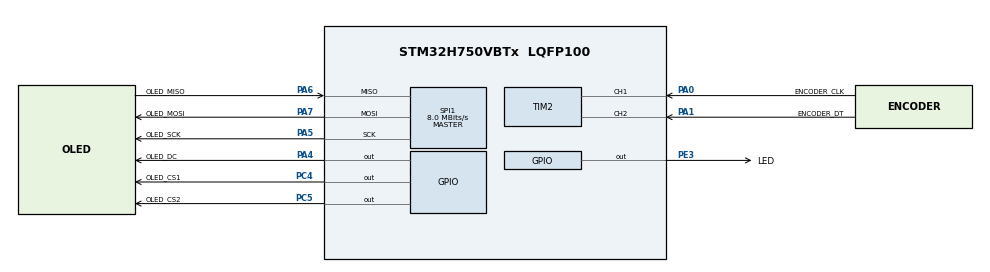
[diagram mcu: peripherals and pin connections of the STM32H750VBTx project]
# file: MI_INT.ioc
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CORTEX_M7.CPU_DCache=Enabled
CORTEX_M7.CPU_ICache=Enabled
CORTEX_M7.default_mode_Activation=1
Mcu.Family=STM32H7
Mcu.Name=STM32H750VBTx
Mcu.Package=LQFP100
NVIC.PriorityGroup=NVIC_PRIORITYGROUP_4
PA0.GPIO_Label=ENCODER_CLK
PA0.Signal=S_TIM2_CH1_ETR
PA1.GPIO_Label=ENCODER_DT
PA1.Signal=S_TIM2_CH2
PA13\ (JTMS/SWDIO).Mode=Serial_Wire
PA13\ (JTMS/SWDIO).Signal=DEBUG_JTMS-SWDIO
PA14\ (JTCK/SWCLK).Mode=Serial_Wire
PA14\ (JTCK/SWCLK).Signal=DEBUG_JTCK-SWCLK
PA4.GPIO_Label=OLED_DC
PA4.Signal=GPIO_Output
PA5.GPIO_Label=OLED_SCK
PA5.Mode=Full_Duplex_Master
PA5.Signal=SPI1_SCK
PA6.GPIO_Label=OLED_MISO
PA6.Mode=Full_Duplex_Master
PA6.Signal=SPI1_MISO
PA7.GPIO_Label=OLED_MOSI
PA7.Mode=Full_Duplex_Master
PA7.Signal=SPI1_MOSI
PC14-OSC32_IN\ (OSC32_IN).Mode=LSE-External-Oscillator
PC14-OSC32_IN\ (OSC32_IN).Signal=RCC_OSC32_IN
PC15-OSC32_OUT\ (OSC32_OUT).Mode=LSE-External-Oscillator
PC15-OSC32_OUT\ (OSC32_OUT).Signal=RCC_OSC32_OUT
PC4.GPIO_Label=OLED_CS1
PC4.Signal=GPIO_Output
PC5.GPIO_Label=OLED_CS2
PC5.Signal=GPIO_Output
PE3.GPIO_Label=LED
PE3.Signal=GPIO_Output
PH0-OSC_IN\ (PH0).Mode=HSE-External-Oscillator
PH0-OSC_IN\ (PH0).Signal=RCC_OSC_IN
PH1-OSC_OUT\ (PH1).Mode=HSE-External-Oscillator
PH1-OSC_OUT\ (PH1).Signal=RCC_OSC_OUT
ProjectManager.HeapSize=0x200
ProjectManager.StackSize=0x800
ProjectManager.TargetToolchain=MDK-ARM V5.32
RCC.ADCFreq_Value=16000000
RCC.APB1Freq_Value=120000000
RCC.APB2Freq_Value=120000000
RCC.APB3Freq_Value=120000000
RCC.APB4Freq_Value=120000000
RCC.CortexFreq_Value=480000000
RCC.D1PPRE=RCC_APB3_DIV2
RCC.D2PPRE1=RCC_APB1_DIV2
RCC.D2PPRE2=RCC_APB2_DIV2
RCC.D3PPRE=RCC_APB4_DIV2
RCC.DIVM1=5
RCC.DIVM2=25
RCC.DIVN1=192
RCC.DIVN2=256
RCC.DIVP2=16
RCC.DIVQ1=5
RCC.HCLKFreq_Value=240000000
RCC.HPRE=RCC_HCLK_DIV2
RCC.PLLFRACN=0
RCC.PLLSourceVirtual=RCC_PLLSOURCE_HSE
RCC.SPI123CLockSelection=RCC_SPI123CLKSOURCE_PLL2
RCC.SYSCLKFreq_VALUE=480000000
RCC.SYSCLKSource=RCC_SYSCLKSOURCE_PLLCLK
RCC.USBFreq_Value=192000000
SH.S_TIM2_CH1_ETR.0=TIM2_CH1,Encoder_Interface
SH.S_TIM2_CH2.0=TIM2_CH2,Encoder_Interface
SPI1.BaudRatePrescaler=SPI_BAUDRATEPRESCALER_2
SPI1.CLKPhase=SPI_PHASE_2EDGE
SPI1.CLKPolarity=SPI_POLARITY_HIGH
SPI1.CalculateBaudRate=8.0 MBits/s
SPI1.DataSize=SPI_DATASIZE_8BIT
SPI1.Direction=SPI_DIRECTION_2LINES
SPI1.Mode=SPI_MODE_MASTER
SPI1.NSSPMode=SPI_NSS_PULSE_DISABLE
SPI1.VirtualType=VM_MASTER
TIM2.EncoderMode=TIM_ENCODERMODE_TI12
VP_MEMORYMAP_VS_MEMORYMAP.Mode=CurAppReg
board=custom

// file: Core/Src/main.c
/* USER CODE BEGIN Header */
/**
 ******************************************************************************
 * @file           : main.c
 * @brief          : Main program body
 ******************************************************************************
 * @attention
 *
 * Copyright (c) 2024 STMicroelectronics.
 * All rights reserved.
 *
 * This software is licensed under terms that can be found in the LICENSE file
 * in the root directory of this software component.
 * If no LICENSE file comes with this software, it is provided AS-IS.
 *
 ******************************************************************************
 */
/* USER CODE END Header */
#include "main.h"
#include "gpio.h"
#include "memorymap.h"
#include "spi.h"
#include "tim.h"

/* USER CODE BEGIN Includes */
#include "oled.h"
#include "stdio.h"
/* USER CODE END Includes */

/* USER CODE BEGIN PV */
uint8_t R_buff[512] = {0};
/* USER CODE END PV */

void SystemClock_Config(void);
static void MPU_Config(void);

int main(void)
{

	/* MPU Configuration--------------------------------------------------------*/
	MPU_Config();

	/* Enable the CPU Cache */

	/* Enable I-Cache---------------------------------------------------------*/
	SCB_EnableICache();

	/* Enable D-Cache---------------------------------------------------------*/
	SCB_EnableDCache();

	/* MCU Configuration--------------------------------------------------------*/

	/* Reset of all peripherals, Initializes the Flash interface and the Systick. */
	HAL_Init();

	/* Configure the system clock */
	SystemClock_Config();

	/* Initialize all configured peripherals */
	MX_GPIO_Init();
	MX_SPI1_Init();
	MX_TIM2_Init();
	/* USER CODE BEGIN 2 */
	char text[128]		  = {0};
	uint8_t encoder_count = 0;

	OLED_Init();
	OLED_ColorTurn(0);
	OLED_DisplayTurn(0);
	OLED_Clear();
	OLED_Display_GB2312_string(0, 0, (uint8_t *)"��ת����������");

	HAL_Delay(500);

	HAL_TIM_Encoder_Start(&htim2, TIM_CHANNEL_ALL);
	/* USER CODE END 2 */

	/* Infinite loop */
	/* USER CODE BEGIN WHILE */
	while (1) {
		encoder_count = TIM2->CNT;
		/* USER CODE END WHILE */

	}
}

void SystemClock_Config(void)
{
	RCC_OscInitTypeDef RCC_OscInitStruct = {0};
	RCC_ClkInitTypeDef RCC_ClkInitStruct = {0};

	/** Supply configuration update enable
	 */
	HAL_PWREx_ConfigSupply(PWR_LDO_SUPPLY);

	/** Configure the main internal regulator output voltage
	 */
	__HAL_PWR_VOLTAGESCALING_CONFIG(PWR_REGULATOR_VOLTAGE_SCALE0);

	while (!__HAL_PWR_GET_FLAG(PWR_FLAG_VOSRDY)) {}

	/** Initializes the RCC Oscillators according to the specified parameters
	 * in the RCC_OscInitTypeDef structure.
	 */
	RCC_OscInitStruct.OscillatorType = RCC_OSCILLATORTYPE_HSE;
	RCC_OscInitStruct.HSEState		 = RCC_HSE_ON;
	RCC_OscInitStruct.PLL.PLLState	 = RCC_PLL_ON;
	RCC_OscInitStruct.PLL.PLLSource	 = RCC_PLLSOURCE_HSE;
	RCC_OscInitStruct.PLL.PLLM		 = 5;
	RCC_OscInitStruct.PLL.PLLN		 = 192;
	RCC_OscInitStruct.PLL.PLLP		 = 2;
	RCC_OscInitStruct.PLL.PLLQ		 = 5;
	RCC_OscInitStruct.PLL.PLLR		 = 2;
	RCC_OscInitStruct.PLL.PLLRGE	 = RCC_PLL1VCIRANGE_2;
	RCC_OscInitStruct.PLL.PLLVCOSEL	 = RCC_PLL1VCOWIDE;
	RCC_OscInitStruct.PLL.PLLFRACN	 = 0;
	if (HAL_RCC_OscConfig(&RCC_OscInitStruct) != HAL_OK) {
		Error_Handler();
	}

	/** Initializes the CPU, AHB and APB buses clocks
	 */
	RCC_ClkInitStruct.ClockType		 = RCC_CLOCKTYPE_HCLK | RCC_CLOCKTYPE_SYSCLK | RCC_CLOCKTYPE_PCLK1 | RCC_CLOCKTYPE_PCLK2 | RCC_CLOCKTYPE_D3PCLK1 | RCC_CLOCKTYPE_D1PCLK1;
	RCC_ClkInitStruct.SYSCLKSource	 = RCC_SYSCLKSOURCE_PLLCLK;
	RCC_ClkInitStruct.SYSCLKDivider	 = RCC_SYSCLK_DIV1;
	RCC_ClkInitStruct.AHBCLKDivider	 = RCC_HCLK_DIV2;
	RCC_ClkInitStruct.APB3CLKDivider = RCC_APB3_DIV2;
	RCC_ClkInitStruct.APB1CLKDivider = RCC_APB1_DIV2;
	RCC_ClkInitStruct.APB2CLKDivider = RCC_APB2_DIV2;
	RCC_ClkInitStruct.APB4CLKDivider = RCC_APB4_DIV2;

	if (HAL_RCC_ClockConfig(&RCC_ClkInitStruct, FLASH_LATENCY_4) != HAL_OK) {
		Error_Handler();
	}
}

/* MPU Configuration */

void MPU_Config(void)
{
	MPU_Region_InitTypeDef MPU_InitStruct = {0};

	/* Disables the MPU */
	HAL_MPU_Disable();

	/** Initializes and configures the Region and the memory to be protected
	 */
	MPU_InitStruct.Enable			= MPU_REGION_ENABLE;
	MPU_InitStruct.Number			= MPU_REGION_NUMBER0;
	MPU_InitStruct.BaseAddress		= 0x0;
	MPU_InitStruct.Size				= MPU_REGION_SIZE_4GB;
	MPU_InitStruct.SubRegionDisable = 0x87;
	MPU_InitStruct.TypeExtField		= MPU_TEX_LEVEL0;
	MPU_InitStruct.AccessPermission = MPU_REGION_NO_ACCESS;
	MPU_InitStruct.DisableExec		= MPU_INSTRUCTION_ACCESS_DISABLE;
	MPU_InitStruct.IsShareable		= MPU_ACCESS_SHAREABLE;
	MPU_InitStruct.IsCacheable		= MPU_ACCESS_NOT_CACHEABLE;
	MPU_InitStruct.IsBufferable		= MPU_ACCESS_NOT_BUFFERABLE;

	HAL_MPU_ConfigRegion(&MPU_InitStruct);
	/* Enables the MPU */
	HAL_MPU_Enable(MPU_PRIVILEGED_DEFAULT);
}

void Error_Handler(void)
{
	__disable_irq();
	while (1) {
	}
}
